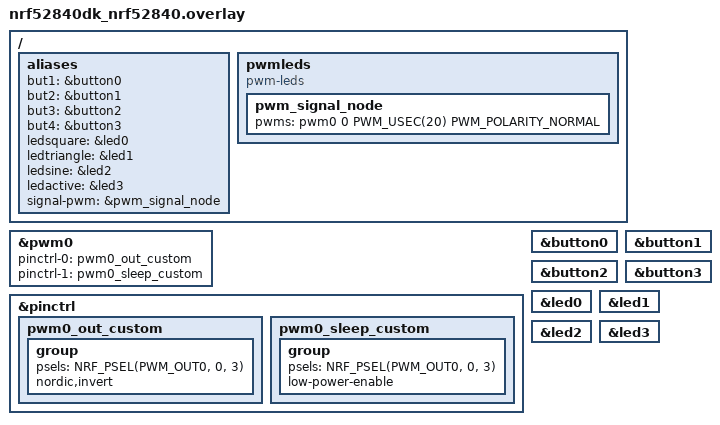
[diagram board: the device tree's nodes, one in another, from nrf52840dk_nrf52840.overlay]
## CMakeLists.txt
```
# SPDX-License-Identifier: Apache-2.0

cmake_minimum_required(VERSION 3.20.0)

find_package(Zephyr REQUIRED HINTS $ENV{ZEPHYR_BASE})
project(pwm)

# CORREÇÃO CRÍTICA: Liste explicitamente todos os ficheiros fontes.
# Isto elimina a instabilidade causada pelo FILE(GLOB) e garante
# que o Linker encontra a 'command_thread_entry'.
target_sources(app PRIVATE
    src/main.c
    src/rtdb.c
    src/output_thread.c
    src/input_thread.c
    src/siggen_thread.c
    src/command_thread.c
    src/gantt_logger.c
)
```

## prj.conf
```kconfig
CONFIG_LOG=y

CONFIG_PWM=y

CONFIG_LED=y

CONFIG_LOG_MODE_IMMEDIATE=y

# Habilita o subsistema de console
CONFIG_CONSOLE=y 

# Habilita o suporte UART (necessário para a comunicação serial)
CONFIG_UART_CONSOLE=y

CONFIG_SERIAL=y
CONFIG_UART_INTERRUPT_DRIVEN=y
CONFIG_CBPRINTF_FP_SUPPORT=y
```

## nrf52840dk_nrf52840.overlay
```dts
/* nrf52840dk_nrf52840.overlay */
#include <dt-bindings/pinctrl/nrf-pinctrl.h>

/ {
    aliases {
        /* Aliases para Botões e LEDs (Mantidos) */
        but1 = &button0;
        but2 = &button1;
        but3 = &button2;
        but4 = &button3;
        ledsquare = &led0;
        ledtriangle = &led1;
        ledsine = &led2;
        ledactive = &led3;

        /* CORREÇÃO CRÍTICA: */
        /* O alias signal-pwm agora aponta para o NÓ LÓGICO, não para o controlador de hardware */
        signal-pwm = &pwm_signal_node; 
    };

    /* Definir um "consumidor" de PWM. É isto que a macro PWM_DT_SPEC_GET espera ler! */
    pwmleds {
        compatible = "pwm-leds";
        pwm_signal_node: pwm_signal_node {
            /* PWM0, Canal 0, Periodo inicial 20us (50kHz), Flags */
            pwms = <&pwm0 0 PWM_USEC(20) PWM_POLARITY_NORMAL>;
        };
    };
};

/* Configuração do Hardware PWM0 (Controlador) */
&pwm0 {
    status = "okay";
    pinctrl-0 = <&pwm0_out_custom>;
    pinctrl-1 = <&pwm0_sleep_custom>;
    pinctrl-names = "default", "sleep";
};

/* Configuração dos Pinos (Pin Control) */
&pinctrl {
    pwm0_out_custom: pwm0_out_custom {
        group {
            /* Mapeia para P0.03 (A0) */
            psels = <NRF_PSEL(PWM_OUT0, 0, 3)>;
            nordic,invert;
        };
    };

    pwm0_sleep_custom: pwm0_sleep_custom {
        group {
            psels = <NRF_PSEL(PWM_OUT0, 0, 3)>;
            low-power-enable;
        };
    };
};

/* Garantir periféricos ativos */
&button0 { status = "okay"; };
&button1 { status = "okay"; };
&button2 { status = "okay"; };
&button3 { status = "okay"; };
&led0 { status = "okay"; };
&led1 { status = "okay"; };
&led2 { status = "okay"; };
&led3 { status = "okay"; };
```

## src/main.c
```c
/**
 * @file main.c
 * @brief System Entry Point and Orchestrator.
 * * This module is responsible for the system initialization sequence:
 * 1. Initializes the Real-Time Database (RTDB) [Implicit].
 * 2. Initializes the Gantt Logger subsystem.
 * 3. Spawns all worker threads in order of criticality.
 * * @note Architecture: The system follows a prioritized preemptive scheduling model
 * compliant with Rate Monotonic Scheduling (RMS) principles.
 */

#include <zephyr/kernel.h>
#include <zephyr/sys/printk.h>

// Incluir TODOS os headers necessários
#include "rtdb.h"
#include "output_thread.h"
#include "input_thread.h"  
#include "siggen_thread.h"  
#include "command_thread.h" 
#include "gantt_logger.h"

/* --- THREAD STACK DEFINITIONS --- */

/** @brief Stack for Signal Generator (High Prio). Requires FPU context. */
K_THREAD_STACK_DEFINE(siggen_thread_stack, SIGGEN_THREAD_STACK_SIZE);
static struct k_thread siggen_thread_data;

/** @brief Stack for Input Processing. */
K_THREAD_STACK_DEFINE(input_thread_stack, INPUT_THREAD_STACK_SIZE);
static struct k_thread input_thread_data;

/** @brief Stack for Command Parser. Needs buffer space for string manipulation. */
K_THREAD_STACK_DEFINE(command_thread_stack, COMMAND_THREAD_STACK_SIZE);
static struct k_thread command_thread_data;

/** @brief Stack for Output/LEDs. Minimal requirements. */
K_THREAD_STACK_DEFINE(output_thread_stack, OUTPUT_THREAD_STACK_SIZE);
static struct k_thread output_thread_data;

/**
 * @brief Main Application Entry Point.
 * * Configures the system and launches the Real-Time Operating System kernel.
 * Never returns.
 */
void main(void) {
    printk("\n--- AWG System: Real-Time Orchestration ---\n");
    

    // Initialize Telemetry
    if (gantt_logger_init() != 0) {
        printk("Failed to init Gantt Logger!\n");
    }

    // 1. T_SigGen: Geração de Sinal (Prioridade ALTA: Prio 2)
    /** * @brief Launches the Critical Signal Generator Thread.
     * Priority: 2 (Highest). Period: 100us (Hard Real-Time).
     */
    k_thread_create(&siggen_thread_data, siggen_thread_stack,
                    K_THREAD_STACK_SIZEOF(siggen_thread_stack),
                    siggen_thread_entry, 
                    NULL, NULL, NULL,
                    SIGGEN_THREAD_PRIORITY, 0, K_NO_WAIT);
    printk("T_SigGen Launched (Prio: %d)\n", SIGGEN_THREAD_PRIORITY);

    
    // 2. T_InputUpdate: Processamento de Botões (Prioridade MÉDIA/ALTA: Prio 5)
    /** * @brief Launches the Input Handling Thread.
     * Priority: 5. Event-driven (Interrupts).
     */
    k_thread_create(&input_thread_data, input_thread_stack,
                    K_THREAD_STACK_SIZEOF(input_thread_stack),
                    input_thread_entry,
                    NULL, NULL, NULL,
                    INPUT_THREAD_PRIORITY, 0, K_NO_WAIT);
    printk("T_InputUpdate Launched (Prio: %d)\n", INPUT_THREAD_PRIORITY);


    // 3. T_CommandParser: Processamento UART (Prioridade MÉDIA/BAIXA: Prio 7)
    /** * @brief Launches the UART Command Parser Thread.
     * Priority: 7. Handles heavy string parsing without blocking SigGen.
     */
    k_thread_create(&command_thread_data, command_thread_stack,
                    K_THREAD_STACK_SIZEOF(command_thread_stack),
                    command_thread_entry,
                    NULL, NULL, NULL,
                    COMMAND_THREAD_PRIORITY, 0, K_NO_WAIT);
    printk("T_CommandParser Launched (Prio: %d)\n", COMMAND_THREAD_PRIORITY);


    // 4. T_OutputUpdate: Controlo de LEDs (Prioridade BAIXA: Prio 10)
    /** * @brief Launches the LED Update Thread.
     * Priority: 10 (Lowest). Visual feedback is non-critical.
     */
    k_thread_create(&output_thread_data, output_thread_stack,
                    K_THREAD_STACK_SIZEOF(output_thread_stack),
                    output_thread_entry,
                    NULL, NULL, NULL,
                    OUTPUT_THREAD_PRIORITY, 0, K_NO_WAIT);
    printk("T_OutputUpdate Launched (Prio: %d)\n", OUTPUT_THREAD_PRIORITY);


    // Start the background logger worker
    gantt_start_logger_thread();

    printk("RTOS system initialization complete.\n");
}
```

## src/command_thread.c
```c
/**
 * @file command_thread.c
 * @brief UART Command Parser Implementation.
 * * Handles UART interrupts/polling and parses commands to control the system.
 */

#include "command_thread.h"
#include "rtdb.h"
#include "gantt_logger.h"
#include <zephyr/drivers/uart.h>
#include <zephyr/sys/printk.h>
#include <string.h>
#include <stdio.h>
#include <stdlib.h>

#define CMD_BUF_SIZE 64
static const struct device *uart_dev = DEVICE_DT_GET(DT_CHOSEN(zephyr_console));
static char rx_buf[CMD_BUF_SIZE];
static int rx_pos = 0;

void send_uart_string(const char *str) {
    for (int i = 0; i < strlen(str); i++) {
        uart_poll_out(uart_dev, str[i]);
    }
}

uint8_t calculate_checksum(char *cmd, int len) {
    uint8_t xor_sum = 0;
    for (int i = 0; i < len; i++) xor_sum ^= cmd[i];
    return xor_sum;
}

void process_command(char *full_cmd) {
    char *start_ptr = strchr(full_cmd, '#');
    char *star_ptr = strchr(full_cmd, '*');

    if (!start_ptr || !star_ptr || star_ptr < start_ptr) {
        send_uart_string("#ERR: Format$\r\n");
        return;
    }

    char *cmd_content = start_ptr + 1;
    int content_len = star_ptr - cmd_content;
    int received_checksum = (int)strtol(star_ptr + 1, NULL, 16);
    uint8_t calculated_checksum = calculate_checksum(cmd_content, content_len);

    if (received_checksum != calculated_checksum) {
        send_uart_string("#NACK$\r\n");
        return;
    }

    *star_ptr = '\0'; 
    bool cmd_ok = false;

    /* --- COMMAND DISPATCHING --- */

    if (strncmp(cmd_content, "SF ", 3) == 0) {
        int freq = atoi(&cmd_content[3]);
        if (freq >= 10 && freq <= 100) {
            rtdb_set_frequency(freq);
            cmd_ok = true;
        }
    }
    else if (strncmp(cmd_content, "SA ", 3) == 0) {
        float amp = (float)strtof(&cmd_content[3], NULL);
        if (amp >= 0.0f && amp <= 2.5f) {
            rtdb_set_amplitude(amp);
            cmd_ok = true;
        }
    }
    else if (strncmp(cmd_content, "SO ", 3) == 0) {
        if (strncmp(&cmd_content[3], "ON", 2) == 0) {
            rtdb_set_output_active(true);
            cmd_ok = true;
        } else if (strncmp(&cmd_content[3], "OFF", 3) == 0) {
            rtdb_set_output_active(false);
            cmd_ok = true;
        }
    }
    /* NEW: Set Wave Type (Required by Specs) */
    else if (strncmp(cmd_content, "SW ", 3) == 0) {
        int type = atoi(&cmd_content[3]);
        if (type >= 0 && type <= 2) {
            rtdb_set_wave_type((wave_type_t)type);
            cmd_ok = true;
        } else {
            send_uart_string("#ERR: Invalid Wave$\r\n");
            return;
        }
    }
    else if (strncmp(cmd_content, "QS", 2) == 0) {
        rtdb_state_t s = rtdb_get_state_copy();
        char msg[64];
        snprintf(msg, sizeof(msg), "#STATUS: W=%d F=%d A=%d O=%d$\r\n", 
                 s.wave_type, s.frequency_hz, (int)s.amplitude_v, s.output_active);
        send_uart_string(msg);
        return; 
    }
    else if (strncmp(cmd_content, "GL ", 3) == 0) {
        if (strncmp(&cmd_content[3], "ON", 2) == 0) {
            gantt_set_enabled(true);
            cmd_ok = true;
        } else if (strncmp(&cmd_content[3], "OFF", 3) == 0) {
            gantt_set_enabled(false);
            cmd_ok = true;
        }
    }
    /* System Stats  */
    else if (strncmp(cmd_content, "ST", 2) == 0) {
        sys_stats_t stats = rtdb_get_stats_copy();
        char msg[160]; 
        
        snprintf(msg, sizeof(msg), 
            "#STATS (us): Sig(C)=%u, In(R)=%u, Cmd(R)=%u, Out(R)=%u$\r\n", 
            stats.wcet_siggen_us, 
            stats.resp_input_us, 
            stats.resp_cmd_us,
            stats.resp_output_us); 
        
        send_uart_string(msg);
        return;
    }

    if (cmd_ok) send_uart_string("#ACK$\r\n");
    else send_uart_string("#ERR: Param$\r\n");
}

void command_thread_entry(void *p1, void *p2, void *p3) {
    uint8_t gantt_id = gantt_register_thread("T_Cmd");
    if (!device_is_ready(uart_dev)) return;
    
    while (1) {
        char c;
        while (uart_poll_in(uart_dev, &c) == 0) {
            if (c == '$') {
                rx_buf[rx_pos] = '\0';
                
                // MEASURE RESPONSE TIME (CMD)
                uint32_t start = k_cycle_get_32();
                
                GANTT_LOG_START(gantt_id);
                process_command(rx_buf);
                GANTT_LOG_END(gantt_id);
                
                uint32_t end = k_cycle_get_32();
                rtdb_update_metric(2, end - start); // ID 2 = Cmd Response

                rx_pos = 0; 
            } else if (rx_pos < CMD_BUF_SIZE - 1) {
                rx_buf[rx_pos++] = c;
            }
        }
        k_msleep(1); 
    }
}
```

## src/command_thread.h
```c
#ifndef COMMAND_THREAD_H
#define COMMAND_THREAD_H

#include <zephyr/kernel.h>

/**
 * @file command_thread.h
 * @brief UART Command Processing Interface.
 * * Handles protocol parsing, checksum validation, and execution of commands
 * received from the host PC.
 */

/* --- CONFIGURATION --- */

/** @brief Stack size. Needs space for string buffers (rx_buf). */
#define COMMAND_THREAD_STACK_SIZE 1024 

/** * @brief Thread Priority (7).
 * Medium/Low Priority. Higher than visual output, but lower than Input and SigGen.
 * Allows parsing complex strings (sprintf/atoi) without causing jitter in the signal output.
 */
#define COMMAND_THREAD_PRIORITY   7 

/* --- API --- */

/**
 * @brief Command Parser Thread Entry Point.
 * * Implements a polling loop on the UART interface to:
 * 1. Assemble incoming characters into packets.
 * 2. Validate Checksums (Data Integrity).
 * 3. Update RTDB based on commands (SF, SA, SO).
 * 4. Control the Gantt Logger state (GL).
 */
void command_thread_entry(void *p1, void *p2, void *p3);

#endif // COMMAND_THREAD_H
```

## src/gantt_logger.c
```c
#include "gantt_logger.h"
#include <zephyr/drivers/uart.h>
#include <zephyr/sys/printk.h>
#include <zephyr/sys/atomic.h>
#include <stdio.h>
#include <string.h>

/* ============================================================================
 * IMPLEMENTAÇÃO DO LOGGER LOCK-FREE
 * ============================================================================
 */

/* --- ESTRUTURA DO RING BUFFER --- */
static struct {
    gantt_event_t events[GANTT_LOG_BUFFER_SIZE];
    atomic_t write_idx;  // Índice de escrita (atómico!)
    atomic_t read_idx;   // Índice de leitura (atómico!)
    atomic_t dropped_events; // Contador de eventos perdidos
} gantt_ring_buffer;

static bool logger_enabled = false; // Começa desligado (Silencioso)

/* --- REGISTO DE THREADS --- */
typedef struct {
    char name[GANTT_MAX_THREAD_NAME];
    bool in_use;
} thread_info_t;

static thread_info_t registered_threads[256];
static atomic_t next_thread_id = ATOMIC_INIT(0);

/* --- UART PARA OUTPUT --- */
static const struct device *uart_dev = DEVICE_DT_GET(DT_CHOSEN(zephyr_console));

/* --- THREAD DE LOGGING --- */
#define LOGGER_THREAD_STACK_SIZE 2048
#define LOGGER_THREAD_PRIORITY   15  // Prioridade MUITO BAIXA

K_THREAD_STACK_DEFINE(logger_thread_stack, LOGGER_THREAD_STACK_SIZE);
static struct k_thread logger_thread_data;

/* ============================================================================
 * FUNÇÃO DE INICIALIZAÇÃO
 * ============================================================================
 */
int gantt_logger_init(void) {
    // Inicializar índices do ring buffer
    atomic_set(&gantt_ring_buffer.write_idx, 0);
    atomic_set(&gantt_ring_buffer.read_idx, 0);
    atomic_set(&gantt_ring_buffer.dropped_events, 0);
    
    // Limpar registo de threads
    memset(registered_threads, 0, sizeof(registered_threads));
    
    if (!device_is_ready(uart_dev)) {
        printk("GANTT LOGGER ERROR: UART not ready\n");
        return -1;
    }
    
    printk("GANTT LOGGER: Initialized (Buffer size: %d events)\n", 
           GANTT_LOG_BUFFER_SIZE);
    
    return 0;
}

/* ============================================================================
 * REGISTO DE THREAD
 * ============================================================================
 */
uint8_t gantt_register_thread(const char *thread_name) {
    uint8_t id = (uint8_t)atomic_inc(&next_thread_id);
    
    if (id >= 256) {
        printk("GANTT ERROR: Too many threads!\n");
        return 255;
    }
    
    strncpy(registered_threads[id].name, thread_name, GANTT_MAX_THREAD_NAME - 1);
    registered_threads[id].name[GANTT_MAX_THREAD_NAME - 1] = '\0';
    registered_threads[id].in_use = true;
    
    //printk("GANTT: Thread '%s' registered with ID %d\n", thread_name, id);
    
    return id;
}

/* ============================================================================
 * LOGGING DE EVENTO (LOCK-FREE!)
 * ============================================================================
 * CRÍTICO: Esta função NUNCA bloqueia!
 */
void gantt_log_event(uint8_t thread_id, gantt_event_type_t event_type) {
    // 1. Obter timestamp (operação rápida, ~50 ciclos)
    uint32_t timestamp_us = k_cyc_to_us_floor32(k_cycle_get_32());
    
    // 2. Obter índice de escrita (atómico, sem lock!)
    uint32_t write_pos = atomic_inc(&gantt_ring_buffer.write_idx);
    write_pos = write_pos % GANTT_LOG_BUFFER_SIZE;
    
    // 3. Verificar se buffer está cheio (sem blocking!)
    uint32_t read_pos = atomic_get(&gantt_ring_buffer.read_idx);
    uint32_t next_write = (write_pos + 1) % GANTT_LOG_BUFFER_SIZE;
    
    if (next_write == read_pos) {
        // Buffer cheio! Descartar evento (melhor que bloquear!)
        atomic_inc(&gantt_ring_buffer.dropped_events);
        return;
    }
    
    // 4. Escrever evento (operação < 10 ciclos)
    gantt_ring_buffer.events[write_pos].timestamp_us = timestamp_us;
    gantt_ring_buffer.events[write_pos].thread_id = thread_id;
    gantt_ring_buffer.events[write_pos].event_type = (uint8_t)event_type;
    gantt_ring_buffer.events[write_pos].reserved = 0;
    
    // NOTA: Sem barriers de memória necessárias porque Zephyr garante
    // ordering em atomic operations no ARM Cortex-M
}

/* ============================================================================
 * THREAD DE LOGGING (Background, baixa prioridade)
 * ============================================================================
 */
static void send_uart_line(const char *line) {
    for (size_t i = 0; i < strlen(line); i++) {
        uart_poll_out(uart_dev, line[i]);
    }
}

static void logger_thread_entry(void *p1, void *p2, void *p3) {
    char csv_line[128];
    
    // Opcional: Enviar cabeçalho apenas quando liga, mas aqui garante que temos sempre um
    // send_uart_line("timestamp_us,thread_id,thread_name,event_type\r\n");
    
    while (1) {
        // --- MODO SILENCIOSO ---
        if (!logger_enabled) {
            // Esvaziar o buffer silenciosamente (discard)
            // Isto garante que quando ligares, vês dados novos e não velhos
            atomic_val_t write_now = atomic_get(&gantt_ring_buffer.write_idx);
            atomic_set(&gantt_ring_buffer.read_idx, write_now);
            
            k_msleep(100); // Dorme e verifica de novo daqui a pouco
            continue; 
        }

        // --- MODO ATIVO (Igual ao que tinhas) ---
        uint32_t read_pos = atomic_get(&gantt_ring_buffer.read_idx);
        uint32_t write_pos = atomic_get(&gantt_ring_buffer.write_idx);
        
        if (read_pos != write_pos) {
            gantt_event_t evt = gantt_ring_buffer.events[read_pos % GANTT_LOG_BUFFER_SIZE];
            
            const char *thread_name = "UNKNOWN";
            if (evt.thread_id < 256 && registered_threads[evt.thread_id].in_use) {
                thread_name = registered_threads[evt.thread_id].name;
            }
            
            snprintf(csv_line, sizeof(csv_line), 
                     "%u,%d,%s,%s\r\n",
                     evt.timestamp_us,
                     evt.thread_id,
                     thread_name,
                     evt.event_type == GANTT_EVENT_START ? "START" : "END");
            
            send_uart_line(csv_line);
            
            atomic_inc(&gantt_ring_buffer.read_idx);
        } else {
            k_msleep(10); // Buffer vazio
        }
    }
}

/* ============================================================================
 * INICIAR THREAD DE LOGGING
 * ============================================================================
 */
void gantt_start_logger_thread(void) {
    k_thread_create(&logger_thread_data, 
                    logger_thread_stack,
                    K_THREAD_STACK_SIZEOF(logger_thread_stack),
                    logger_thread_entry,
                    NULL, NULL, NULL,
                    LOGGER_THREAD_PRIORITY, 0, K_NO_WAIT);
    
    printk("GANTT LOGGER: Background thread launched\n");
}

void gantt_set_enabled(bool enable) {
    logger_enabled = enable;
    printk("GANTT: Logging %s\n", enable ? "ENABLED" : "DISABLED");
}
```

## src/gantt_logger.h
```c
#ifndef GANTT_LOGGER_H
#define GANTT_LOGGER_H

#include <zephyr/kernel.h>
#include <stdbool.h>

/**
 * @file gantt_logger.h
 * @brief Low-Overhead Lock-Free Logger for Gantt Chart generation.
 * * This module records thread execution events (START/END) into a 
 * circular buffer (Ring Buffer) using atomic operations.
 * * @note This implementation is "Lock-Free" to ensure that High-Priority
 * Real-Time threads (like SigGen) are NEVER blocked by logging operations.
 */

/* --- CONFIGURATION --- */
#define GANTT_LOG_BUFFER_SIZE 512   /**< Buffer size (Power of 2 for optimization) */
#define GANTT_MAX_THREAD_NAME 16    /**< Max chars for thread name */

/**
 * @brief Event Types for Gantt Chart.
 */
typedef enum {
    GANTT_EVENT_START = 0,  /**< Thread started processing (CPU busy) */
    GANTT_EVENT_END   = 1   /**< Thread finished processing (Yield/Sleep) */
} gantt_event_type_t;

/**
 * @brief Event Structure (Optimized for memory alignment).
 * Size: 8 bytes per event.
 */
typedef struct {
    uint32_t timestamp_us;  /**< Timestamp in microseconds */
    uint8_t  thread_id;     /**< Unique Thread ID */
    uint8_t  event_type;    /**< START or END */
    uint16_t reserved;      /**< Padding */
} gantt_event_t;

/* ============================================================================
 * API FUNCTIONS
 * ============================================================================
 */

/**
 * @brief Initializes the Logger subsystem.
 * Resets ring buffer indices and registers.
 * @return 0 on success.
 */
int gantt_logger_init(void);

/**
 * @brief Registers a thread for logging.
 * * Assigns a unique ID to the thread name for efficient logging.
 * * @param thread_name Human-readable name (e.g., "T_SigGen").
 * @return Assigned Thread ID (uint8_t).
 */
uint8_t gantt_register_thread(const char *thread_name);

/**
 * @brief Logs a thread event (Critical Path).
 * * This function is LOCK-FREE and generic. It uses atomic_inc to
 * reserve space in the ring buffer.
 * If the buffer is full, the event is silently dropped to preserve system timing.
 * * @param thread_id ID obtained from gantt_register_thread().
 * @param event_type GANTT_EVENT_START or GANTT_EVENT_END.
 */
void gantt_log_event(uint8_t thread_id, gantt_event_type_t event_type);

/**
 * @brief Controls the Logging Output.
 * * Used to enable/disable the stream of CSV data to UART.
 * * @param enable true to start sending data, false to silence UART.
 */
void gantt_set_enabled(bool enable);

/**
 * @brief Starts the background worker thread.
 * * This thread runs at Low Priority to offload data from the ring buffer
 * to the UART interface without disturbing Real-Time tasks.
 */
void gantt_start_logger_thread(void);

/* --- MACROS --- */
#define GANTT_LOG_START(id) gantt_log_event(id, GANTT_EVENT_START)
#define GANTT_LOG_END(id)   gantt_log_event(id, GANTT_EVENT_END)

#endif // GANTT_LOGGER_H
```

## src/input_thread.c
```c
/**
 * @file input_thread.c
 * @brief Input Thread Implementation.
 * * Handles 4 buttons via interrupts and updates RTDB.
 * * Includes visual feedback via printk (UART) for user interaction.
 */

#include "input_thread.h"
#include "rtdb.h"
#include "gantt_logger.h"
#include <zephyr/drivers/gpio.h>
#include <zephyr/sys/printk.h>

/* --- DEVICE TREE ALIASES --- */
static const struct gpio_dt_spec but1 = GPIO_DT_SPEC_GET(DT_ALIAS(but1), gpios);
static const struct gpio_dt_spec but2 = GPIO_DT_SPEC_GET(DT_ALIAS(but2), gpios);
static const struct gpio_dt_spec but3 = GPIO_DT_SPEC_GET(DT_ALIAS(but3), gpios);
static const struct gpio_dt_spec but4 = GPIO_DT_SPEC_GET(DT_ALIAS(but4), gpios);

static struct gpio_callback button_cb_data;
K_SEM_DEFINE(input_sem, 0, 1);
static volatile uint32_t button_event_mask = 0;

/* --- INTERRUPT HANDLER --- */
void button_handler(const struct device *dev, struct gpio_callback *cb, uint32_t pins) {
    if (pins & BIT(but1.pin)) { button_event_mask |= BIT(0); }
    if (pins & BIT(but2.pin)) { button_event_mask |= BIT(1); }
    if (pins & BIT(but3.pin)) { button_event_mask |= BIT(2); }
    if (pins & BIT(but4.pin)) { button_event_mask |= BIT(3); }
    k_sem_give(&input_sem);
}

/* --- BUTTON LOGIC WITH FEEDBACK --- */

// SW1: Wave Type
void handle_but1(void) { 
    wave_type_t current = rtdb_get_state_copy().wave_type;
    wave_type_t next = (current == WAVE_SQUARE) ? WAVE_TRIANGLE : (current == WAVE_TRIANGLE ? WAVE_SINE : WAVE_SQUARE);
    rtdb_set_wave_type(next);
    
    // Feedback Strings
    const char *names[] = {"SQUARE", "TRIANGLE", "SINE"};
    printk("[INPUT] Wave: %s\n", names[next]);
}

// SW2: Frequency
void handle_but2(void) { 
    int current = rtdb_get_state_copy().frequency_hz;
    int next = current + 10;
    if (next > 90) next = 10;
    
    rtdb_set_frequency(next);
    printk("[INPUT] Freq: %d Hz\n", next);
}

// SW3: Output Toggle
void handle_but3(void) { 
    bool next = !rtdb_get_state_copy().output_active;
    rtdb_set_output_active(next); 
    printk("[INPUT] Output: %s\n", next ? "ON" : "OFF");
}

// SW4: Amplitude
void handle_but4(void) { 
    float current = rtdb_get_state_copy().amplitude_v;
    float next = current + 0.5f;
    if (next > 2.5f) next = 0.0f;
    
    rtdb_set_amplitude(next);
    
    // Print hack para evitar erros de float no printf se não estiver configurado
    printk("[INPUT] Amp: %d.%d V\n", (int)next, (int)((next - (int)next) * 10)); 
}

/* --- CONFIGURATION --- */
int configure_button(const struct gpio_dt_spec *but) {
    if (!device_is_ready(but->port)) return -1;
    int ret = gpio_pin_configure_dt(but, GPIO_INPUT | GPIO_PULL_UP);
    if (ret < 0) return ret;
    return gpio_pin_interrupt_configure_dt(but, GPIO_INT_EDGE_TO_ACTIVE);
}

/* --- THREAD ENTRY POINT --- */
void input_thread_entry(void *p1, void *p2, void *p3) {
    uint8_t gantt_id = gantt_register_thread("T_Input");

    if (configure_button(&but1) < 0 || configure_button(&but2) < 0 ||
        configure_button(&but3) < 0 || configure_button(&but4) < 0) {
        printk("INPUT FATAL: Failed to config buttons\n");
        return;
    }

    gpio_init_callback(&button_cb_data, button_handler, 
                       BIT(but1.pin) | BIT(but2.pin) | BIT(but3.pin) | BIT(but4.pin));
    gpio_add_callback(but1.port, &button_cb_data);

    printk("INPUT: Buttons active.\n");

    while (1) {
        k_sem_take(&input_sem, K_FOREVER);
        
        // START PROFILING
        uint32_t start = k_cycle_get_32();

        k_msleep(50); // Debounce
        
        GANTT_LOG_START(gantt_id);
        uint32_t events = button_event_mask;
        button_event_mask = 0; 

        if (events & BIT(0)) handle_but1();
        if (events & BIT(1)) handle_but2();
        if (events & BIT(2)) handle_but3();
        if (events & BIT(3)) handle_but4();
        
        GANTT_LOG_END(gantt_id);

        // END PROFILING
        uint32_t end = k_cycle_get_32();
        rtdb_update_metric(1, end - start); // ID 1 = Input Response Time
    }
}
```

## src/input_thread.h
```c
#ifndef INPUT_THREAD_H
#define INPUT_THREAD_H

#include <zephyr/kernel.h>

/**
 * @file input_thread.h
 * @brief Human-Machine Interface (HMI) Handling Module.
 * * This module manages the 4 physical buttons on the nRF52840-DK.
 * It uses interrupts and semaphores to react to user input with low latency.
 */

/* --- CONFIGURAÇÃO DA THREAD --- */

/** @brief Stack size in bytes. Sufficient for basic GPIO and RTDB calls. */
#define INPUT_THREAD_STACK_SIZE 1024 

/** @brief Priority level (5). Higher than UART (7) and Output (10), lower than SigGen (2). */
#define INPUT_THREAD_PRIORITY   5 

/* --- API PÚBLICA --- */

/**
 * @brief Entry point for the Input Processing Thread.
 * * This thread sleeps on a semaphore waiting for GPIO interrupts.
 * When a button is pressed, it wakes up, debounces the signal, 
 * updates the RTDB state, and logs the event to the Gantt chart.
 */
void input_thread_entry(void *p1, void *p2, void *p3);

#endif // INPUT_THREAD_H
```

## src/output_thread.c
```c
#include "output_thread.h"
#include "rtdb.h"
#include <zephyr/drivers/gpio.h>
#include <zephyr/sys/printk.h>
#include "gantt_logger.h"

#define LED_SQUARE_NODE   DT_ALIAS(ledsquare)   // Era o led0/led1
#define LED_TRIANGLE_NODE DT_ALIAS(ledtriangle) // Era o led1/led2
#define LED_SINE_NODE     DT_ALIAS(ledsine)     // Era o led2/led3
#define LED_ACTIVE_NODE   DT_ALIAS(ledactive)   // Era o led3/led4

static const struct gpio_dt_spec led_sq_spec = GPIO_DT_SPEC_GET(LED_SQUARE_NODE, gpios);
static const struct gpio_dt_spec led_tri_spec = GPIO_DT_SPEC_GET(LED_TRIANGLE_NODE, gpios);
static const struct gpio_dt_spec led_sin_spec = GPIO_DT_SPEC_GET(LED_SINE_NODE, gpios);
static const struct gpio_dt_spec led_act_spec = GPIO_DT_SPEC_GET(LED_ACTIVE_NODE, gpios);

void output_thread_entry(void *p1, void *p2, void *p3) {
    uint8_t gantt_id = gantt_register_thread("T_Output");
    // Validação de segurança
    if (!device_is_ready(led_sq_spec.port) || !device_is_ready(led_tri_spec.port) ||
        !device_is_ready(led_sin_spec.port) || !device_is_ready(led_act_spec.port)) {
        printk("Erro: Um ou mais LEDs não estão prontos.\n");
        return;
    }

    // Configuração
    gpio_pin_configure_dt(&led_sq_spec, GPIO_OUTPUT_INACTIVE);
    gpio_pin_configure_dt(&led_tri_spec, GPIO_OUTPUT_INACTIVE);
    gpio_pin_configure_dt(&led_sin_spec, GPIO_OUTPUT_INACTIVE);
    gpio_pin_configure_dt(&led_act_spec, GPIO_OUTPUT_INACTIVE);

    while (1) {

        uint32_t start = k_cycle_get_32();

        GANTT_LOG_START(gantt_id);
        // Obter cópia segura do estado
        rtdb_state_t state = rtdb_get_state_copy();

        // 1. Atualizar LED de Status Geral (ON/OFF)
        gpio_pin_set_dt(&led_act_spec, state.output_active);

        // 2. Resetar todos os LEDs de tipo de onda
        gpio_pin_set_dt(&led_sq_spec, 0);
        gpio_pin_set_dt(&led_tri_spec, 0);
        gpio_pin_set_dt(&led_sin_spec, 0);

        // 3. Ligar APENAS o LED correspondente
        // Nota: Só mostramos o tipo se o output estiver ativo? O PDF não especifica,
        // mas geralmente mostra-se a configuração mesmo com output OFF.
        switch (state.wave_type) {
            case WAVE_SQUARE:
                gpio_pin_set_dt(&led_sq_spec, 1); // AGORA SIM, CUMPRIU A SPEC
                break;
            case WAVE_TRIANGLE:
                gpio_pin_set_dt(&led_tri_spec, 1);
                break;
            case WAVE_SINE:
                gpio_pin_set_dt(&led_sin_spec, 1);
                break;
        }

        // Debugging Output
        //printk("[%u] OUTPUT (Prio 10): A atualizar LEDs...\n", k_uptime_get_32());
        GANTT_LOG_END(gantt_id);

        uint32_t end = k_cycle_get_32();
        rtdb_update_metric(3, end - start); // ID 3 = Output Response Time
        // Frequência de atualização de 10Hz é suficiente para UI.
        // 1000ms (1s) é demasiado lento, o utilizador sente lag ao carregar no botão.
        k_msleep(100); 
    }
}
```

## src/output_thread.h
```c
#ifndef OUTPUT_THREAD_H
#define OUTPUT_THREAD_H

/**
 * @file output_thread.h
 * @brief Visual Feedback (LED) Interface.
 * * Updates the physical LEDs on the board to reflect the internal state
 * of the system (Waveform type, Output ON/OFF).
 */

/* --- CONFIGURATION --- */

/** @brief Stack size. Minimal requirements. */
#define OUTPUT_THREAD_STACK_SIZE 2048 

/** * @brief Thread Priority (10).
 * Low Priority. This is a "Soft Real-Time" task. If it lags by 50ms, 
 * the human eye won't notice, so it yields CPU to everything else.
 */
#define OUTPUT_THREAD_PRIORITY   10 

/* --- API --- */

/**
 * @brief Output Thread Entry Point.
 * * Periodically polls the RTDB state and updates GPIO pins.
 * Rate limited to avoid consuming unnecessary CPU cycles.
 */
void output_thread_entry(void *p1, void *p2, void *p3);

#endif // OUTPUT_THREAD_H
```

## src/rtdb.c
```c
/**
 * @file rtdb.c
 * @brief RTDB Implementation.
 */
#include "rtdb.h"

K_MUTEX_DEFINE(rtdb_mutex);

// Internal state storage
static rtdb_state_t rtdb_current_state = {
    .wave_type = WAVE_SQUARE,
    .amplitude_v = 0.0f,
    .frequency_hz = 10,
    .output_active = false
};

// Internal statistics storage
static sys_stats_t global_stats = {0};

void rtdb_update_metric(int metric_id, uint32_t duration_cycles) {
    // Convert cycles to microseconds immediately for storage
    uint32_t us = k_cyc_to_us_floor32(duration_cycles);
    
    // Simple atomic 32-bit writes (No mutex needed for stats to avoid priority inversion)
    switch(metric_id) {
        case 0: // SigGen (Critical)
            if(us > global_stats.wcet_siggen_us) global_stats.wcet_siggen_us = us;
            break;
        case 1: // Input
            if(us > global_stats.resp_input_us) global_stats.resp_input_us = us;
            break;
        case 2: // Command
            if(us > global_stats.resp_cmd_us) global_stats.resp_cmd_us = us;
            break;
        case 3: // Output
            if(us > global_stats.resp_output_us) global_stats.resp_output_us = us; 
            break;
    }
}

sys_stats_t rtdb_get_stats_copy(void) {
    return global_stats;
}

// --- Thread-Safe Setters ---

void rtdb_set_amplitude(float amp_v) {
    k_mutex_lock(&rtdb_mutex, K_FOREVER);
    if (amp_v < 0.0f) amp_v = 0.0f;
    if (amp_v > 2.5f) amp_v = 2.5f;
    rtdb_current_state.amplitude_v = amp_v;
    k_mutex_unlock(&rtdb_mutex);
}

void rtdb_set_frequency(int freq_hz) {
    k_mutex_lock(&rtdb_mutex, K_FOREVER);
    if (freq_hz < 1) freq_hz = 1; 
    if (freq_hz > 100) freq_hz = 100; 
    rtdb_current_state.frequency_hz = freq_hz;
    k_mutex_unlock(&rtdb_mutex);
}

void rtdb_set_output_active(bool active) {
    k_mutex_lock(&rtdb_mutex, K_FOREVER);
    rtdb_current_state.output_active = active;
    k_mutex_unlock(&rtdb_mutex);
}

void rtdb_set_wave_type(wave_type_t new_type) {
    k_mutex_lock(&rtdb_mutex, K_FOREVER);
    rtdb_current_state.wave_type = new_type;
    k_mutex_unlock(&rtdb_mutex);
}

rtdb_state_t rtdb_get_state_copy(void) {
    rtdb_state_t copy;
    k_mutex_lock(&rtdb_mutex, K_FOREVER);
    copy = rtdb_current_state;
    k_mutex_unlock(&rtdb_mutex);
    return copy;
}
```

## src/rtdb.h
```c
#ifndef RTDB_H
#define RTDB_H

#include <zephyr/kernel.h>
#include <stdbool.h>

/**
 * @file rtdb.h
 * @brief Real-Time Database (RTDB) Module.
 * * This module acts as the central Shared Memory region for the system.
 * It implements Thread-Safe access using Mutexes to prevent Race Conditions
 * and ensure data consistency between high-priority (SigGen) and low-priority tasks.
 */

/* ============================================================================
 * DATA STRUCTURES
 * ============================================================================
 */

/**
 * @brief Supported Waveform Types.
 */
typedef enum {
    WAVE_SQUARE = 0,    /**< Square wave (Digital Pulse) */
    WAVE_TRIANGLE = 1,  /**< Triangle wave (Linear Ramp) */
    WAVE_SINE = 2       /**< Sine wave (Look-Up Table based) */
} wave_type_t;

/**
 * @brief System State Structure.
 * Holds the current configuration of the waveform generator.
 */
typedef struct {
    int frequency_hz;      /**< Frequency in Hertz (10-100Hz) */
    float amplitude_v;     /**< Amplitude in Volts (0.0-2.5V) */
    wave_type_t wave_type; /**< Current waveform type */
    bool output_active;    /**< Master Output Switch (ON/OFF) */
} rtdb_state_t;

/**
 * @brief Real-Time System Statistics (Profiling).
 * Stores the maximum measured execution times (High-Water Mark).
 */
typedef struct {
    uint32_t wcet_siggen_us;  /**< Worst-Case Execution Time for Hard RT Task (SigGen) */
    uint32_t resp_input_us;   /**< Response Time for Input Task (Exec + Blocking) */
    uint32_t resp_cmd_us;     /**< Response Time for Command Task (Exec + Blocking) */
    uint32_t resp_output_us;
} sys_stats_t;

/* ============================================================================
 * PUBLIC API (Thread-Safe)
 * ============================================================================
 */

/**
 * @brief Initializes the Real-Time Database.
 * Must be called before any thread tries to access the state.
 */
void rtdb_init(void);

/**
 * @brief Updates a specific timing metric.
 * * Used by worker threads to report their execution duration.
 * Keeps the maximum value observed (Peak Hold).
 * * @param metric_id 0=SigGen(WCET), 1=Input(Response), 2=Command(Response).
 * @param duration_cycles Duration in CPU cycles.
 */
void rtdb_update_metric(int metric_id, uint32_t duration_cycles);

/**
 * @brief Gets a copy of the system statistics.
 * * @return A sys_stats_t struct containing the max times in microseconds.
 */
sys_stats_t rtdb_get_stats_copy(void);

// --- Setters ---
void rtdb_set_frequency(int freq);
void rtdb_set_amplitude(float amp);
void rtdb_set_wave_type(wave_type_t type);
void rtdb_set_output_active(bool active);

/**
 * @brief Gets a consistent copy of the full system state.
 * * Locks the mutex to ensure atomic read.
 * * @return A copy of rtdb_state_t.
 */
rtdb_state_t rtdb_get_state_copy(void);

#endif // RTDB_H
```

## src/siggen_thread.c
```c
/**
 * @file siggen_thread.c
 * @brief Signal Generator Thread (Hard Real-Time).
 * * Features:
 * - Waveform Synthesis (Sine/Triangle/Square) via PWM.
 * - Software Profiling to validate RMS assumptions.
 */

#include "siggen_thread.h"
#include "rtdb.h"
#include "gantt_logger.h"
#include <zephyr/drivers/pwm.h>
#include <zephyr/sys/printk.h>

/* --- HARDWARE CONFIG --- */
#define PWM_NODE DT_ALIAS(signal_pwm)
#define PWM_CARRIER_NS 20000 
#define BOARD_VDD_VOLTAGE 3.3f 

/* --- LUT (100 points) --- */
static const float sine_lut[100] = {
    0.500f, 0.531f, 0.563f, 0.594f, 0.625f, 0.655f, 0.684f, 0.713f, 0.740f, 0.766f,
    0.790f, 0.813f, 0.835f, 0.855f, 0.873f, 0.890f, 0.905f, 0.918f, 0.930f, 0.940f,
    0.949f, 0.957f, 0.963f, 0.969f, 0.973f, 0.976f, 0.978f, 0.979f, 0.979f, 0.978f,
    0.976f, 0.973f, 0.969f, 0.963f, 0.957f, 0.949f, 0.940f, 0.930f, 0.918f, 0.905f,
    0.890f, 0.873f, 0.855f, 0.835f, 0.813f, 0.790f, 0.766f, 0.740f, 0.713f, 0.684f,
    0.655f, 0.625f, 0.594f, 0.563f, 0.531f, 0.500f, 0.469f, 0.437f, 0.406f, 0.375f,
    0.345f, 0.316f, 0.287f, 0.260f, 0.234f, 0.210f, 0.187f, 0.165f, 0.145f, 0.127f,
    0.110f, 0.095f, 0.082f, 0.070f, 0.060f, 0.051f, 0.043f, 0.037f, 0.031f, 0.027f,
    0.024f, 0.022f, 0.021f, 0.021f, 0.021f, 0.022f, 0.024f, 0.027f, 0.031f, 0.037f,
    0.043f, 0.051f, 0.060f, 0.070f, 0.082f, 0.095f, 0.110f, 0.127f, 0.145f, 0.165f,
    0.187f, 0.210f, 0.234f, 0.260f, 0.287f, 0.316f, 0.345f, 0.375f, 0.406f, 0.437f
};

static const struct pwm_dt_spec pwm_dev = PWM_DT_SPEC_GET(PWM_NODE);
static struct k_timer sample_timer;
static volatile int sample_index = 0;
static volatile wave_type_t current_wave_type = WAVE_SQUARE;
static volatile float current_amplitude_v = 0.0f;
static volatile bool is_output_active = false;

/* --- TIMER HANDLER (CRITICAL SECTION) --- */
void sample_timer_handler(struct k_timer *dummy) {
    // 1. START PROFILING
    uint32_t start = k_cycle_get_32();

    if (!is_output_active) return;
    
    float shape_value = 0.0f; 
    switch (current_wave_type) {
        case WAVE_SINE: shape_value = sine_lut[sample_index]; break;
        case WAVE_TRIANGLE: 
            if (sample_index < 50) shape_value = (float)sample_index / 50.0f;
            else shape_value = (float)(100 - sample_index) / 50.0f;
            break;
        default: 
            if (sample_index < 50) shape_value = 1.0f; else shape_value = 0.0f;
            break;
    }
    
    float target_v = current_amplitude_v;
    if (target_v > 2.5f) target_v = 2.5f; 
    if (target_v < 0.0f) target_v = 0.0f;
    float scale_factor = target_v / BOARD_VDD_VOLTAGE;
    uint32_t pulse_ns = (uint32_t)(shape_value * scale_factor * PWM_CARRIER_NS);
    
    pwm_set_dt(&pwm_dev, PWM_CARRIER_NS, pulse_ns);
    
    sample_index++;
    if (sample_index >= 100) sample_index = 0;

    // 2. END PROFILING & REPORT
    uint32_t end = k_cycle_get_32();
    rtdb_update_metric(0, end - start); // ID 0 = SigGen WCET
}

void siggen_thread_entry(void *p1, void *p2, void *p3) {
    uint8_t gantt_id = gantt_register_thread("T_SigGen");

    if (!pwm_is_ready_dt(&pwm_dev)) {
        printk("SIGGEN FATAL: PWM device not ready!\n");
        return;
    }

    k_timer_init(&sample_timer, sample_timer_handler, NULL);
    
    int last_freq = -1;
    bool last_active = false;

    while (1) {
        GANTT_LOG_START(gantt_id);
        
        // Critical: Minimize time here
        rtdb_state_t state = rtdb_get_state_copy();
        current_wave_type = state.wave_type;
        current_amplitude_v = state.amplitude_v;
        is_output_active = state.output_active;

        if (state.output_active) {
            if (!last_active || state.frequency_hz != last_freq) {
                int safe_freq = state.frequency_hz;
                if (safe_freq < 1) safe_freq = 1;
                uint32_t sample_period_us = 1000000 / (safe_freq * 100);
                k_timer_start(&sample_timer, K_USEC(sample_period_us), K_USEC(sample_period_us));
            }
        } else {
            if (last_active) {
                k_timer_stop(&sample_timer);
                pwm_set_dt(&pwm_dev, PWM_CARRIER_NS, 0); 
            }
        }
        last_freq = state.frequency_hz;
        last_active = state.output_active;

        GANTT_LOG_END(gantt_id);
        k_msleep(100);
    }
}
```

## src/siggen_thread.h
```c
#ifndef SIGGEN_THREAD_H
#define SIGGEN_THREAD_H

#include <zephyr/kernel.h>

/**
 * @file siggen_thread.h
 * @brief Signal Generator Thread Interface.
 * * This module is the "Hard Real-Time" core of the project.
 * It is responsible for calculating waveform samples and updating the PWM duty cycle
 * within a strict deadline (100us).
 */

/* --- CONFIGURATION --- */

/** @brief Stack size. Needs to be generous for floating-point operations (FPU). */
#define SIGGEN_THREAD_STACK_SIZE 1024 

/** * @brief Thread Priority (2).
 * VERY HIGH PRIORITY. In Zephyr, lower number = higher priority.
 * This ensures the signal generator preempts all other tasks (Input, UART, LEDs).
 */
#define SIGGEN_THREAD_PRIORITY   2 

/* --- API --- */

/**
 * @brief Signal Generator Thread Entry Point.
 * * Contains the main loop that:
 * 1. Reads configuration from RTDB.
 * 2. Feeds the Watchdog Timer.
 * 3. Manages the hardware timer for precise sample output.
 */
void siggen_thread_entry(void *p1, void *p2, void *p3);

/**
 * @brief Retrieves the measured Worst-Case Execution Time (WCET).
 * * Accesses the internal profiling variable safely.
 * @return The maximum execution time measured so far (in microseconds).
 */
uint32_t get_siggen_wcet_us(void);

#endif // SIGGEN_THREAD_H
```
